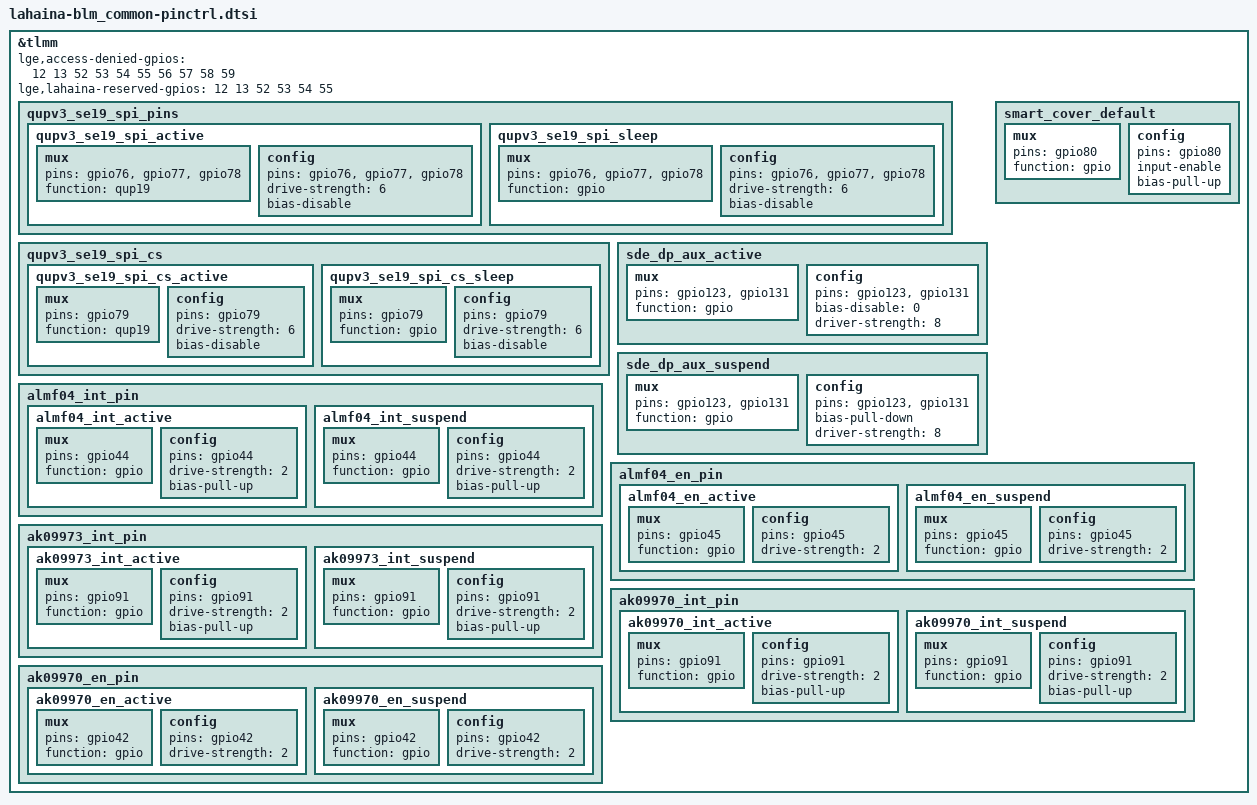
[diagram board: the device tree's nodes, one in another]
&tlmm {
	lge,access-denied-gpios = <12 13 52 53 54 55 56 57 58 59>;
	lge,lahaina-reserved-gpios = <12 13 52 53 54 55>;

	qupv3_se19_spi_pins {
		qupv3_se19_spi_active: qupv3_se19_spi_active {
			mux {
				pins = "gpio76", "gpio77", "gpio78";
				function = "qup19";
			};
			config {
				pins = "gpio76", "gpio77", "gpio78";
				drive-strength = <6>;
				bias-disable;
			};
		};
		qupv3_se19_spi_sleep: qupv3_se19_spi_sleep {
			mux {
				pins = "gpio76", "gpio77", "gpio78";
				function = "gpio";
			};
			config {
				pins = "gpio76", "gpio77", "gpio78";
				drive-strength = <6>;
				bias-disable;
			};
		};
	};

	qupv3_se19_spi_cs {
		qupv3_se19_spi_cs_active: qupv3_se19_spi_cs_active {
			mux {
				pins = "gpio79";
				function = "qup19";
			};
			config {
				pins = "gpio79";
				drive-strength = <6>;
				bias-disable;
			};
		};
		qupv3_se19_spi_cs_sleep: qupv3_se19_spi_cs_sleep {
			mux {
				pins = "gpio79";
				function = "gpio";
			};
			config {
				pins = "gpio79";
				drive-strength = <6>;
				bias-disable;
			};
		};
	};

	sde_dp_aux_active:sde_dp_aux_active {
		mux {
			pins = "gpio123", "gpio131";
			function = "gpio";
		};

		config {
			pins = "gpio123", "gpio131";
			bias-disable = <0>;
			driver-strength = <8>;
		};
	};

	sde_dp_aux_suspend:sde_dp_aux_suspend {
		mux {
			pins = "gpio123", "gpio131";
			function = "gpio";
		};

		config {
			pins = "gpio123", "gpio131";
			bias-pull-down;
			driver-strength = <8>;
		};
	};

	smart_cover_default:smart_cover_default {
		mux {
			pins = "gpio80";
			function = "gpio";
		};

		config {
			pins = "gpio80";
			input-enable;
			bias-pull-up;
		};
	};

	almf04_int_pin {
		almf04_int_active: almf04_int_active {
			mux {
				pins = "gpio44";
				function = "gpio";
			};
			config {
				pins = "gpio44";
				drive-strength = <2>;   /* 2 MA */
				bias-pull-up;           /* PULL UP*/
			};
		};

		almf04_int_suspend: almf04_int_suspend {
			mux {
				pins = "gpio44";
				function = "gpio";
			};
			config {
				pins = "gpio44";
				drive-strength = <2>;   /* 2 MA */
				bias-pull-up;           /* PULL UP */
			};
		};
	};

	almf04_en_pin {
		almf04_en_active: almf04_en_active {
			mux {
				pins = "gpio45";
				function = "gpio";
			};
			config {
				pins = "gpio45";
				drive-strength = <2>;   /* 2 MA */
			};
		};
		almf04_en_suspend: almf04_en_suspend {
			mux {
				pins = "gpio45";
				function = "gpio";
			};
			config {
				pins = "gpio45";
				drive-strength = <2>;   /* 2 MA */
			};
		};
	};

	ak09973_int_pin {
		ak09973_int_active: ak09973_int_active {
			mux {
				pins = "gpio91";
				function = "gpio";
			};
			config {
				pins = "gpio91";
				drive-strength = <2>;   /* 2 MA */
				bias-pull-up;           /* PULL UP*/
			};
		};
		ak09973_int_suspend: ak09973_int_suspend {
			mux {
				pins = "gpio91";
				function = "gpio";
			};
			config {
				pins = "gpio91";
				drive-strength = <2>;   /* 2 MA */
				bias-pull-up;           /* PULL UP */
			};
		};
	};

	ak09970_int_pin {
		ak09970_int_active: ak09970_int_active {
			mux {
				pins = "gpio91";
				function = "gpio";
			};
			config {
				pins = "gpio91";
				drive-strength = <2>;   /* 2 MA */
				bias-pull-up;           /* PULL UP*/
			};
		};
		ak09970_int_suspend: ak09970_int_suspend {
			mux {
				pins = "gpio91";
				function = "gpio";
			};
			config {
				pins = "gpio91";
				drive-strength = <2>;   /* 2 MA */
				bias-pull-up;           /* PULL UP */
			};
		};
	};

	ak09970_en_pin {
		ak09970_en_active: ak09970_en_active {
			mux {
				pins = "gpio42";
				function = "gpio";
			};
			config {
				pins = "gpio42";
				drive-strength = <2>;   /* 2 MA */
			};
		};
		ak09970_en_suspend: ak09970_en_suspend {
			mux {
				pins = "gpio42";
				function = "gpio";
			};
			config {
				pins = "gpio42";
				drive-strength = <2>;   /* 2 MA */
			};
		};
	};
};
